# nrf7140_sysctrl register map
Vendor: Nordic Semiconductor; Series: nRF71; File version: 1
Registers are 32-bit, read-write, reset 0x0 unless marked. A register's access mark holds for its fields unless they carry their own. Offsets are from the block's base; [hi:lo] are bit positions; lines under a group give offsets from that group; 'fields as' and 'values as' point back to an identical list.

## VREGAO0V8 — VREGAO0V8 peripheral
Base 0x5F964000
0x100 EVENTS_READY — Power up done
  [0] EVENTS_READY
    0=NotGenerated (Event not generated); 1=Generated (Event generated)
0x104 EVENTS_SETTLED — Settled flag for MODE handshake
  [0] EVENTS_SETTLED
    values as EVENTS_READY.EVENTS_READY
0x108 EVENTS_BPREADY — Bypass ready flag
  [0] EVENTS_BPREADY
    values as EVENTS_READY.EVENTS_READY
0x10C EVENTS_IOUTCMPHP — HP mode analog current comparator
  [0] EVENTS_IOUTCMPHP
    values as EVENTS_READY.EVENTS_READY
0x110 EVENTS_IOUTCMPLP — LP mode analog current comparator
  [0] EVENTS_IOUTCMPLP
    values as EVENTS_READY.EVENTS_READY
0x114 EVENTS_LP2HP — Current consumption above threshold
  [0] EVENTS_LP2HP
    values as EVENTS_READY.EVENTS_READY
0x118 EVENTS_HP2LP — Current consumption below threshold
  [0] EVENTS_HP2LP
    values as EVENTS_READY.EVENTS_READY
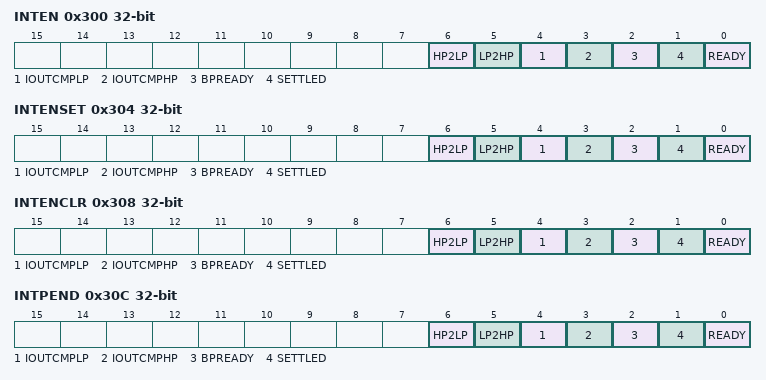
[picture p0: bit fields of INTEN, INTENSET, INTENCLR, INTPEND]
0x300 INTEN — Enable or disable interrupt
  [all] fields
    0=Disabled; 1=Enabled
  [6] HP2LP — Enable or disable interrupt for event HP2LP
  [5] LP2HP — Enable or disable interrupt for event LP2HP
  [4] IOUTCMPLP — Enable or disable interrupt for event IOUTCMPLP
  [3] IOUTCMPHP — Enable or disable interrupt for event IOUTCMPHP
  [2] BPREADY — Enable or disable interrupt for event BPREADY
  [1] SETTLED — Enable or disable interrupt for event SETTLED
  [0] READY — Enable or disable interrupt for event READY
0x304 INTENSET — Enable interrupt
  [all] fields
    on read: 0=Disabled (Read: Disabled); 1=Enabled (Read: Enabled) | on write: 1=Set (Enable)
  [6] HP2LP — Write '1' to enable interrupt for event HP2LP
  [5] LP2HP — Write '1' to enable interrupt for event LP2HP
  [4] IOUTCMPLP — Write '1' to enable interrupt for event IOUTCMPLP
  [3] IOUTCMPHP — Write '1' to enable interrupt for event IOUTCMPHP
  [2] BPREADY — Write '1' to enable interrupt for event BPREADY
  [1] SETTLED — Write '1' to enable interrupt for event SETTLED
  [0] READY — Write '1' to enable interrupt for event READY
0x308 INTENCLR — Disable interrupt
  [all] fields
    on read: 0=Disabled (Read: Disabled); 1=Enabled (Read: Enabled) | on write: 1=Clear (Disable)
  [6] HP2LP — Write '1' to disable interrupt for event HP2LP
  [5] LP2HP — Write '1' to disable interrupt for event LP2HP
  [4] IOUTCMPLP — Write '1' to disable interrupt for event IOUTCMPLP
  [3] IOUTCMPHP — Write '1' to disable interrupt for event IOUTCMPHP
  [2] BPREADY — Write '1' to disable interrupt for event BPREADY
  [1] SETTLED — Write '1' to disable interrupt for event SETTLED
  [0] READY — Write '1' to disable interrupt for event READY
0x30C INTPEND ro — Pending interrupts
  [all] fields
    on read: 0=NotPending (Read: Not pending); 1=Pending (Read: Pending)
  [6] HP2LP — Read pending status of interrupt for event HP2LP
  [5] LP2HP — Read pending status of interrupt for event LP2HP
  [4] IOUTCMPLP — Read pending status of interrupt for event IOUTCMPLP
  [3] IOUTCMPHP — Read pending status of interrupt for event IOUTCMPHP
  [2] BPREADY — Read pending status of interrupt for event BPREADY
  [1] SETTLED — Read pending status of interrupt for event SETTLED
  [0] READY — Read pending status of interrupt for event READY
0x400 STATUS ro — Voltage regulator status
  [1:0] MODE — Current voltage regulator mode
    0=High power mode; 1=Low power refresh mode; 2=Ultra-low power refresh mode; 3=Bypass mode
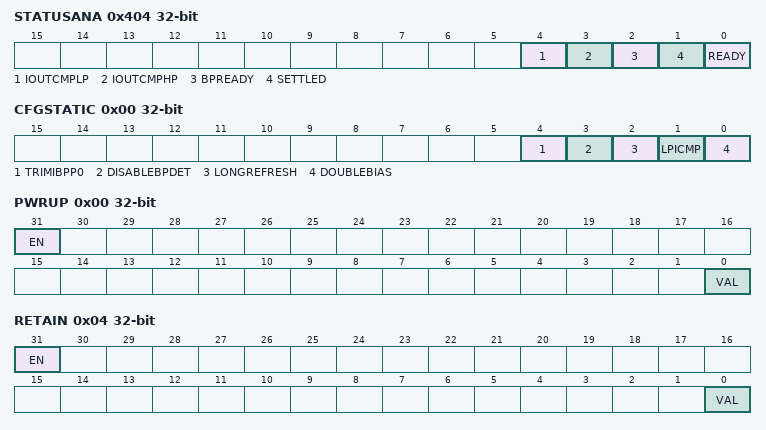
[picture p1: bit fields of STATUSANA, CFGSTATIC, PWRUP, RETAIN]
0x404 STATUSANA ro — Status of analog module output signals
  [4] IOUTCMPLP — Current value of the IOUTCMPLP signal from the analog module
  [3] IOUTCMPHP — Current value of the IOUTCMPHP signal from the analog module
  [2] BPREADY — Current value of the BPREADY signal from the analog module
  [1] SETTLED — Current value of the SETTLED signal from the analog module
  [0] READY — Current value of the READY signal from the analog module
0x410 CONFIG group — Unspecified
  0x00 CFGSTATIC — VREGAO0V8 static CFG configuration
    [4] TRIMIBPP0 — LSB of IBPP trim
    [3] DISABLEBPDET — Configuration for disabling the BPDET
      0=Disabled (Configuration disabled); 1=Enabled (Configuration enabled)
    [2] LONGREFRESH — Configuration for long refresh timer
      values as DISABLEBPDET
    [1] LPICMP — Configuration for LP ICMP
      values as DISABLEBPDET
    [0] DOUBLEBIAS — Configuration for double bias
      values as DISABLEBPDET
0x440 TRIM group — Unspecified
  0x00 IREF reset 0x8 — Local current reference trimming
    [6:0] VAL — Current reference trimming value
  0x04 HIGHPOWER — High power mode output voltage offset trimming
    [3:0] VAL — Voltage offset trimming value
  0x08 LOWPOWER — Low power mode output voltage offset trimming
    [3:0] VAL — Voltage offset trimming value.
  0x0C ULTRALOWPOWER — Ultra low power mode ripple trimming
    [1:0] VAL — Ripple trimming value.
      1=5mV (Unspecified); 0=15mV (Unspecified); 3=25mV (Unspecified); 2=35mV (Unspecified)
  0x10 BPDET — BP detector offset trimming
    [3:0] VAL — Voltage offset trimming value.
0x480 MIRROR reset 0x1 — Enable LOCK for mirrored registers
  [0] LOCK — Lock for mirrored registers
    0=Disabled (Lock disabled); 1=Enabled (Lock enabled)
0x484 VOUT reset 0x6 — Output voltage programming
  [2:0] VAL — Output voltage value
0x488 MODE — Voltage regulator mode
  [2:0] MODE
    0=Automatically handled by the peripheral; 1=High power mode; 2=Low power refresh mode; 3=Ultra-low power refresh mode; 4=Bypass forced mode
0x48C ITHRESHOLD reset 0xA — Current threshold for mode transistion
  [3:0] VAL — Current consumption
0x500 OVERRIDE group — Unspecified
  0x00 PWRUP — Override the PWRUP signal to the analog module
    [31] EN — Enable the override
      0=Disabled (Override is disabled); 1=Enabled (Override is enabled)
    [0] VAL — Override value for the signal
  0x04 RETAIN — Override the RETAIN signal to the analog module
    fields as OVERRIDE.PWRUP
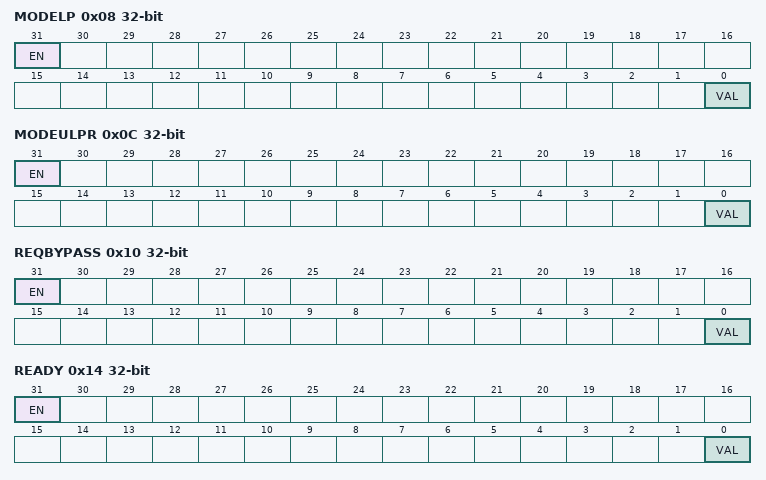
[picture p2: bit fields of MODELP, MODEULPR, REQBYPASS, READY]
  0x08 MODELP — Override the MODE LP signal to the analog module
    fields as OVERRIDE.PWRUP
  0x0C MODEULPR — Override the MODE ULPR signal to the analog module
    fields as OVERRIDE.PWRUP
  0x10 REQBYPASS — Override the REQ BYPASS signal to the analog module
    fields as OVERRIDE.PWRUP
  0x14 READY — Override the READY signal from the analog module
    [31] EN — Enable the override
      values as OVERRIDE.PWRUP.EN
    [0] VAL — Current value of the signal
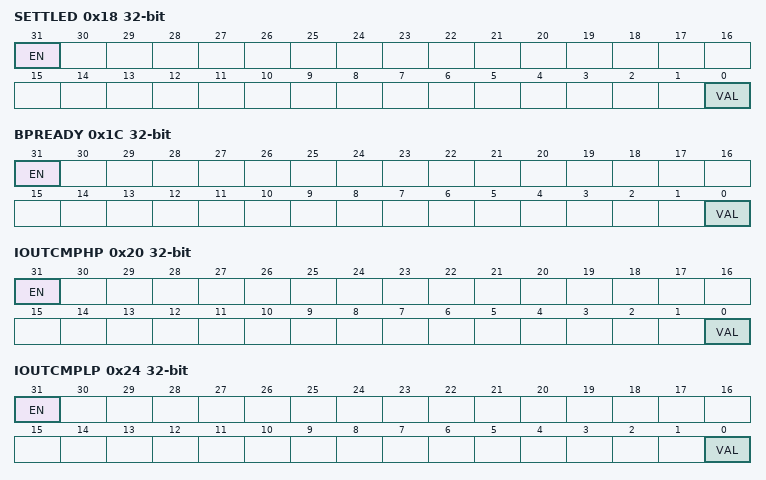
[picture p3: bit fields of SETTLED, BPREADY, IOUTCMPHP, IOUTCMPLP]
  0x18 SETTLED — Override the SETTLED signal from the analog module
    fields as OVERRIDE.READY
  0x1C BPREADY — Override the BP READY signal from the analog module
    fields as OVERRIDE.READY
  0x20 IOUTCMPHP — Override the IOUTCMP_HP signal from the analog module
    fields as OVERRIDE.READY
  0x24 IOUTCMPLP — Override the IOUTCMP_LP signal from the analog module
    fields as OVERRIDE.READY
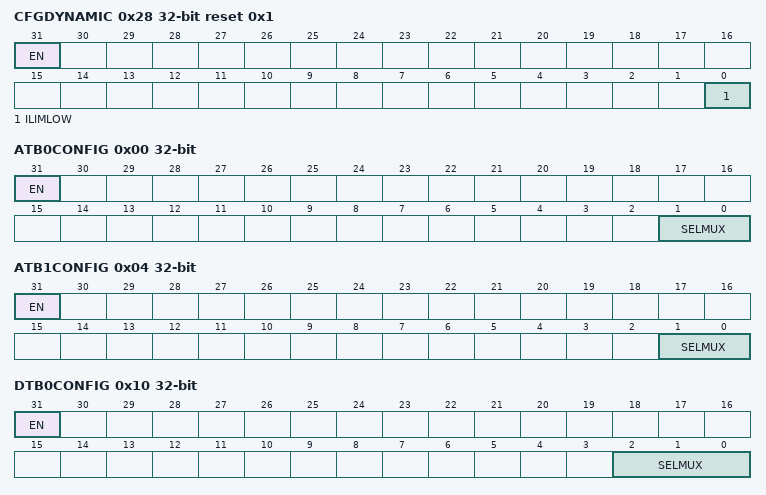
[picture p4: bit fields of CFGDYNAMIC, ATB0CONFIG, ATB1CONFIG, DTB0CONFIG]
  0x28 CFGDYNAMIC reset 0x1 — Override VREGAO0V8 dynamic CFG configuration
    [31] EN — Enable the override
      values as OVERRIDE.PWRUP.EN
    [0] ILIMLOW — Current limit low configuration for the voltage regulator
      values as CONFIG.CFGSTATIC.DISABLEBPDET
0x600 DFT group — Unspecified
  0x00 ATB0CONFIG — Analog Test Bus 0 (ATB0) configuration
    [31] EN — Enable the analog test bus
      0=Disabled (Analog test bus is disabled); 1=Enabled (Analog test bus is enabled)
    [1:0] SELMUX — Select multiplexer for ATB0
      0=ExtVref (External Vref); 1=Ibpsr8u (Internal 8uA current reference); 2=Ibpp50n; 3=VSS
  0x04 ATB1CONFIG — Analog Test Bus 1 (ATB1) configuration
    [31] EN — Enable the analog test bus
      values as DFT.ATB0CONFIG.EN
    [1:0] SELMUX — Select multiplexer for ATB1
      0=VrefHP (HP vref); 1=Vref0V9Dvt; 2=VrefLp (Buffered VREF_LP); 3=Vfb
  0x10 DTB0CONFIG — Digital Test Bus 0 (DTB0) configuration
    [31] EN — Enable the digital test bus
      0=Disabled (Digital test bus is disabled); 1=Enabled (Digital test bus is enabled)
    [2:0] SELMUX — Select multiplexer for DTB0
      0=IcmpHp; 1=MbiasIbpsrSettled; 2=ModeLp; 3=ReadyLdo; 4=BpReady; 5=IbppReady; 6=PwrupIbpsr (Internal 4uA current reference powerup); 7=PwrupCoreHp (High Power core powerup)
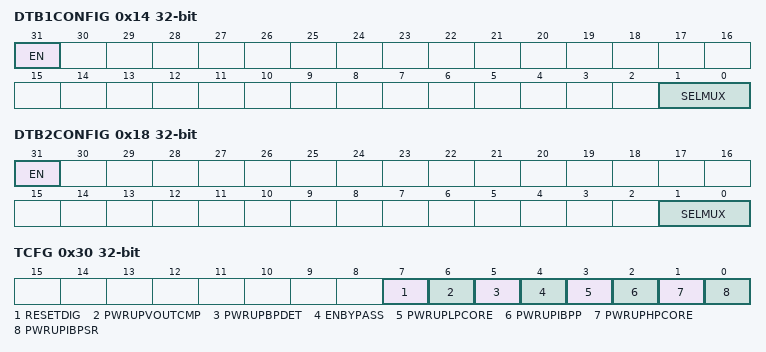
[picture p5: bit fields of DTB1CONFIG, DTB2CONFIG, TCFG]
  0x14 DTB1CONFIG — Digital Test Bus 1 (DTB1) configuration
    [31] EN — Enable the digital test bus
      values as DFT.DTB0CONFIG.EN
    [1:0] SELMUX — Select multiplexer for DTB1
      0=Bpdet; 1=IbpsrSettled; 2=ModeUlp; 3=SettledLdo
  0x18 DTB2CONFIG — Digital Test Bus 2 (DTB2) configuration
    [31] EN — Enable the digital test bus
      values as DFT.DTB0CONFIG.EN
    [1:0] SELMUX — Select multiplexer for DTB2
      0=IcmpLp; 1=VoutCmp; 2=ReqBp; 3=CalCmp
  0x1C DTB3CONFIG — Digital Test Bus 3 (DTB3) configuration
    [27] PWRUPDELTEST — Enable the PWRUP delay test circuit
      0=Disabled (PWRUP delay test circuit is disabled); 1=Enabled (PWRUP delay test circuit is enabled)
  0x30 TCFG — Test mode configuration
    [all] fields
      0=Disabled (Unspecified); 1=Enabled (Unspecified)
    [7] RESETDIG
    [6] PWRUPVOUTCMP
    [5] PWRUPBPDET
    [4] ENBYPASS
    [3] PWRUPLPCORE
    [2] PWRUPIBPP
    [1] PWRUPHPCORE
    [0] PWRUPIBPSR
  0x34 CALEN — Calibration enable
    [0] CALEN
      0=ATCMPOff; 1=ATCMPOn
  0x38 CALCMP ro — Calibration compare
    [0] CALCMP
